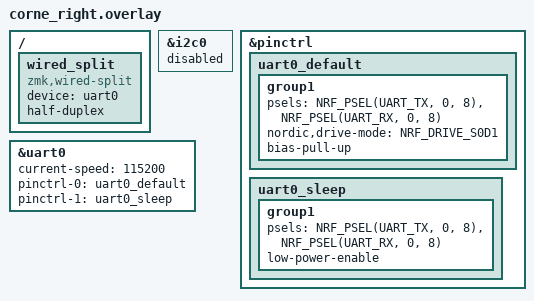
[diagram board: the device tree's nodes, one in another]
/*
 * Wired split UART overlay for right (peripheral) half.
 * Half-duplex UART via shared TRRS data line on P0.08.
 * Both TX and RX on the same pin with open-drain to avoid bus contention.
 */

#include <dt-bindings/pinctrl/nrf-pinctrl.h>

/* Disable I2C — uart0 shares the same nRF SERIAL0 peripheral */
&i2c0 {
    status = "disabled";
};

&pinctrl {
    uart0_default: uart0_default {
        /* Delete stale group2 (TX on P0.06) inherited from nice_nano-pinctrl.dtsi */
        /delete-node/ group2;
        group1 {
            psels = <NRF_PSEL(UART_TX, 0, 8)>,
                    <NRF_PSEL(UART_RX, 0, 8)>;
            /* Open-drain TX so the remote side can also drive the shared line */
            nordic,drive-mode = <NRF_DRIVE_S0D1>;
            bias-pull-up;
        };
    };
    uart0_sleep: uart0_sleep {
        group1 {
            psels = <NRF_PSEL(UART_TX, 0, 8)>,
                    <NRF_PSEL(UART_RX, 0, 8)>;
            low-power-enable;
        };
    };
};

&uart0 {
    status = "okay";
    current-speed = <115200>;
    pinctrl-0 = <&uart0_default>;
    pinctrl-1 = <&uart0_sleep>;
    pinctrl-names = "default", "sleep";
};

/ {
    wired_split {
        compatible = "zmk,wired-split";
        device = <&uart0>;
        half-duplex;
    };
};
